# STM32H7A3x register map
File version: 1.8
CPU: CM7 r0p1, little endian, MPU, FPU, 4 interrupt priority bits
Registers are 32-bit, read-write, reset 0x0 unless marked. A register's access mark holds for its fields unless they carry their own. Offsets are from the block's base; [hi:lo] are bit positions; {n}, {i} and the like mark numbered series.

## SWPMI — Single Wire Protocol Master Interface
Base 0x40008800
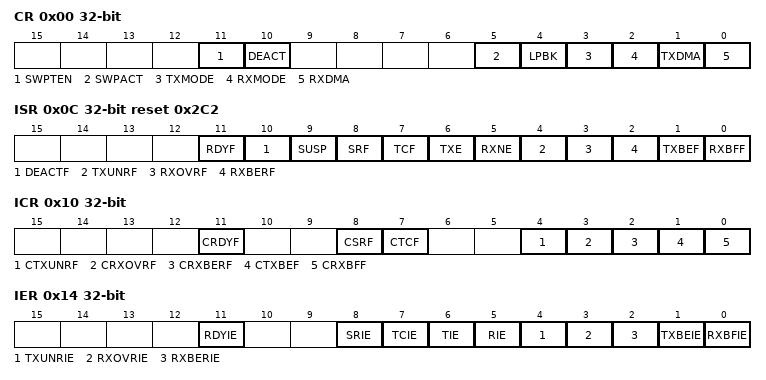
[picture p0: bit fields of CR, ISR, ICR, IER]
0x00 CR — SWPMI Configuration/Control register
  [11] SWPTEN — Single wire protocol master transceiver enable
  [10] DEACT — Single wire protocol master interface deactivate
  [5] SWPACT — Single wire protocol master interface activate
  [4] LPBK — Loopback mode enable
  [3] TXMODE — Transmission buffering mode
  [2] RXMODE — Reception buffering mode
  [1] TXDMA — Transmission DMA enable
  [0] RXDMA — Reception DMA enable
0x04 BRR reset 0x1 — SWPMI Bitrate register
  [7:0] BR — Bitrate prescaler
0x0C ISR ro reset 0x2C2 — SWPMI Interrupt and Status register
  [11] RDYF — transceiver ready flag
  [10] DEACTF — DEACTIVATED flag
  [9] SUSP — SUSPEND flag
  [8] SRF — Slave resume flag
  [7] TCF — Transfer complete flag
  [6] TXE — Transmit data register empty
  [5] RXNE — Receive data register not empty
  [4] TXUNRF — Transmit underrun error flag
  [3] RXOVRF — Receive overrun error flag
  [2] RXBERF — Receive CRC error flag
  [1] TXBEF — Transmit buffer empty flag
  [0] RXBFF — Receive buffer full flag
0x10 ICR wo — SWPMI Interrupt Flag Clear register
  [11] CRDYF — Clear transceiver ready flag
  [8] CSRF — Clear slave resume flag
  [7] CTCF — Clear transfer complete flag
  [4] CTXUNRF — Clear transmit underrun error flag
  [3] CRXOVRF — Clear receive overrun error flag
  [2] CRXBERF — Clear receive CRC error flag
  [1] CTXBEF — Clear transmit buffer empty flag
  [0] CRXBFF — Clear receive buffer full flag
0x14 IER — SWPMI Interrupt Enable register
  [11] RDYIE — Transceiver ready interrupt enable
  [8] SRIE — Slave resume interrupt enable
  [7] TCIE — Transmit complete interrupt enable
  [6] TIE — Transmit interrupt enable
  [5] RIE — Receive interrupt enable
  [4] TXUNRIE — Transmit underrun error interrupt enable
  [3] RXOVRIE — Receive overrun error interrupt enable
  [2] RXBERIE — Receive CRC error interrupt enable
  [1] TXBEIE — Transmit buffer empty interrupt enable
  [0] RXBFIE — Receive buffer full interrupt enable
0x18 RFL ro — SWPMI Receive Frame Length register
  [4:0] RFL — Receive frame length
0x1C TDR wo — SWPMI Transmit data register
  [31:0] TD — Transmit data
0x20 RDR ro — SWPMI Receive data register
  [31:0] RD — received data
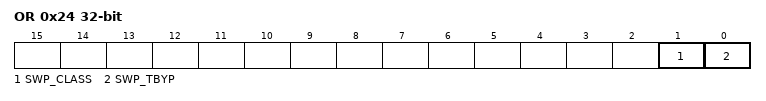
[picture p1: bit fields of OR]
0x24 OR — SWPMI Option register
  [1] SWP_CLASS — SWP class selection
  [0] SWP_TBYP — SWP transceiver bypass

## TIM6 — Basic timers
Base 0x40001000
Same registers: TIM7 0x40001400
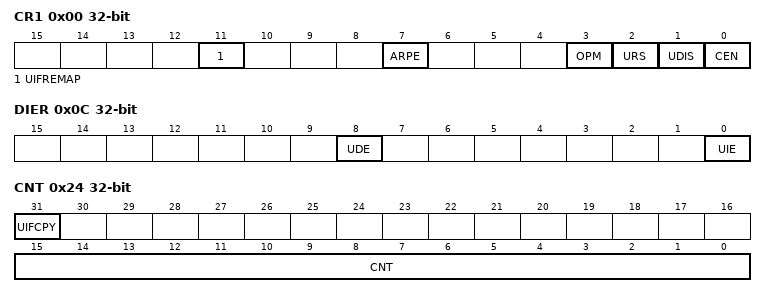
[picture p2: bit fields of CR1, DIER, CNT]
0x00 CR1 — control register 1
  [11] UIFREMAP — UIF status bit remapping
  [7] ARPE — Auto-reload preload enable
  [3] OPM — One-pulse mode
  [2] URS — Update request source
  [1] UDIS — Update disable
  [0] CEN — Counter enable
0x04 CR2 — control register 2
  [6:4] MMS — Master mode selection
0x0C DIER — DMA/Interrupt enable register
  [8] UDE — Update DMA request enable
  [0] UIE — Update interrupt enable
0x10 SR — status register
  [0] UIF — Update interrupt flag
0x14 EGR wo — event generation register
  [0] UG — Update generation
0x24 CNT — counter
  [31] UIFCPY — UIF Copy
  [15:0] CNT — Low counter value
0x28 PSC — prescaler
  [15:0] PSC — Prescaler value
0x2C ARR — auto-reload register
  [15:0] ARR — Low Auto-reload value

## NVIC — Nested Vectored Interrupt Controller
Base 0xE000E100
{0x0+4i} ISER{i} (i=0..2) — Interrupt Set-Enable Register
  [31:0] SETENA
{0x80+4i} ICER{i} (i=0..2) — Interrupt Clear-Enable Register
  [31:0] CLRENA
{0x100+4i} ISPR{i} (i=0..2) — Interrupt Set-Pending Register
  [31:0] SETPEND
{0x180+4i} ICPR{i} (i=0..2) — Interrupt Clear-Pending Register
  [31:0] CLRPEND
{0x200+4i} IABR{i} ro (i=0..2) — Interrupt Active Bit Register
  [31:0] ACTIVE
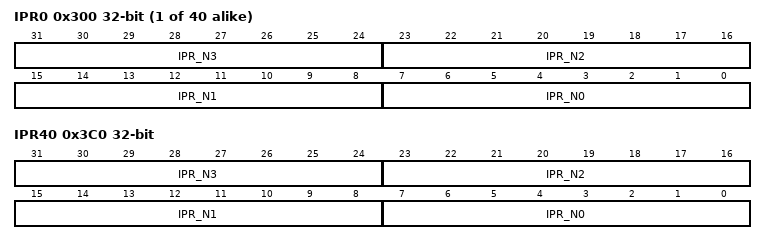
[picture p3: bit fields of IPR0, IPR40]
{0x300+4i} IPR{i} (i=0..39) — Interrupt Priority Register
  [8n+7:8n] IPR_N{n} (n=0..3)
0x3A0 ISER3 — Interrupt Set-Enable Register
  [31:0] SETENA
0x3A4 ISER4 — Interrupt Set-Enable Register
  [31:0] SETENA
0x3A8 ICER3 — Interrupt Clear-Enable Register
  [31:0] CLRENA
0x3AC ICER4 — Interrupt Clear-Enable Register
  [31:0] CLRENA
0x3B0 ISPR3 — Interrupt Set-Pending Register
  [31:0] SETPEND
0x3B4 ISPR4 — Interrupt Set-Pending Register
  [31:0] SETPEND
0x3B8 IABR3 ro — Interrupt Active Bit Register
  [31:0] ACTIVE
0x3BC IABR4 ro — Interrupt Active Bit Register
  [31:0] ACTIVE
0x3C0 IPR40 — Interrupt Priority Register
  [8n+7:8n] IPR_N{n} (n=0..3)
